# nrf54h20_enga_sysctrl register map
Vendor: Nordic Semiconductor; Series: nRF54h; File version: 1
Registers are 32-bit, read-write, reset 0x0 unless marked. A register's access mark holds for its fields unless they carry their own. Offsets are from the block's base; [hi:lo] are bit positions; lines under a group give offsets from that group; 'fields as' and 'values as' point back to an identical list.

## VREGMRAM130_S — VREGMRAM peripheral 0
Base 0x5F969000
Same registers: VREGMRAM131_S 0x5F96A000
0x00 TASKS_PWRUP wo — Power up the VREF and VPR regulator
  [0] TASKS_PWRUP
    1=Trigger task
0x04 TASKS_PWRDOWN wo — Power down the VREF and VPR regulator
  [0] TASKS_PWRDOWN
    1=Trigger task
0x100 EVENTS_READY — The regulator power up done
  [0] EVENTS_READY
    0=NotGenerated (Event not generated); 1=Generated (Event generated)
0x300 INTEN — Enable or disable interrupt
  [0] READY — Enable or disable interrupt for event READY
    0=Disabled; 1=Enabled
0x304 INTENSET — Enable interrupt
  [0] READY — Write '1' to enable interrupt for event READY
    on read: 0=Disabled (Read: Disabled); 1=Enabled (Read: Enabled) | on write: 1=Set (Enable)
0x308 INTENCLR — Disable interrupt
  [0] READY — Write '1' to disable interrupt for event READY
    on read: 0=Disabled (Read: Disabled); 1=Enabled (Read: Enabled) | on write: 1=Clear (Disable)
0x30C INTPEND ro — Pending interrupts
  [0] READY — Read pending status of interrupt for event READY
    on read: 0=NotPending (Read: Not pending); 1=Pending (Read: Pending)
0x400 STATUSANA ro — Status of analog module output signals
  [0] READY — Current value of the READY signal from the analog module
0x440 TRIM group — Unspecified
  0x00 VBG reset 0x8 — Bandgap voltage buffer trim
    [3:0] VAL — Voltage reference trimming value
  0x04 BIAS — Bias trim
    [1:0] VAL — Bias trimming value
      0=Val450nA (Bias trimming is 450nA); 1=Val530nA (Bias trimming is 530nA); 2=Val400nA (Bias trimming is 400nA)
  0x08 VPR reset 0x8 — VPR reference voltage trim for 1.2V VPR
    [3:0] VAL — Voltage offset trimming value
  0x0C VREF reset 0x8 — VREF reference voltage trim for 0.6V VREF
    [3:0] VAL — Voltage offset trimming value
0x480 MIRROR reset 0x1 — Enable LOCK for mirrored registers
  [0] LOCK — Lock for mirrored registers
    0=Disabled (Lock disabled); 1=Enabled (Lock enabled)
0x484 VPRBLEED reset 0x1 — Enable VPR output load current
  [0] EN — Enable
    0=Disabled (VPR output load current disabled); 1=Enabled (VPR output load current enabled)
0x488 VREFADAPTIVEBIAS reset 0x1 — Adaptive bias enable for VREF
  [0] EN — Enable
    0=Disabled (Adaptive bias is disabled); 1=Enabled (Adaptive bias is enabled)
0x48C VPRADAPTIVEBIAS reset 0x1 — Adaptive bias enable for VPR
  fields as VREFADAPTIVEBIAS
0x490 MODE — MRAM regulator mode
  [0] MODE — Enable
    0=Normal mode; 1=Retain mode
0x500 OVERRIDE group — Unspecified
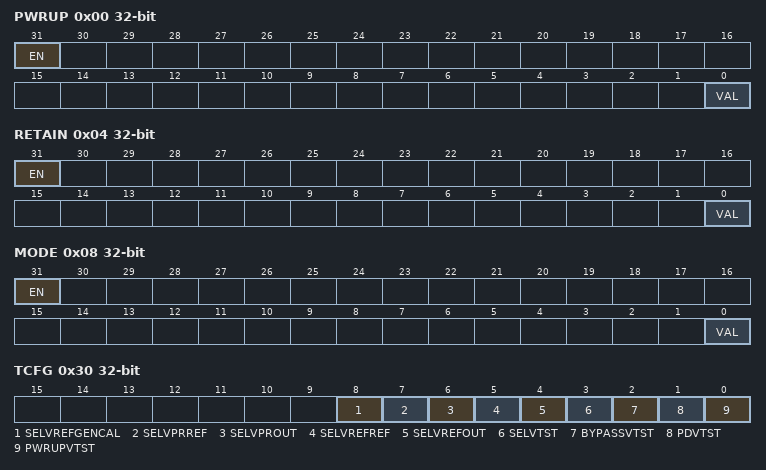
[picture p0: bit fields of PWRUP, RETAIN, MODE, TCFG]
  0x00 PWRUP — Override the PWRUP signal to the analog module
    [31] EN — Enable the override
      0=Disabled (Override is disabled); 1=Enabled (Override is enabled)
    [0] VAL — Override value for the signal
  0x04 RETAIN — Override the RETAIN signal to the analog module
    fields as OVERRIDE.PWRUP
  0x08 MODE — Override the MODE signal to the analog module
    [31] EN — Enable the override
      values as OVERRIDE.PWRUP.EN
    [0] VAL — Current value of the signal
0x600 DFT group — Unspecified
  0x00 ATB0CONFIG — Analog Test Bus 0 (ATB0) configuration
    [31] EN — Enable the analog test bus
      0=Disabled (Analog test bus is disabled); 1=Enabled (Analog test bus is enabled)
    [3] VTST
      0=Disabled (Unspecified); 1=Enabled (Unspecified)
    [2] VPR — VPR 1V2
      0=Disabled (Unspecified); 1=Enabled (Unspecified)
    [1] VREF — VREF 0V6
      0=Disabled (Unspecified); 1=Enabled (Unspecified)
    [0] IB300NA
      0=Disabled (Unspecified); 1=Enabled (Unspecified)
    [3:0] SELMUX — SELMUX 4-bit single signal
  0x04 ATB1CONFIG — Analog Test Bus 1 (ATB1) configuration
    [31] EN — Enable the analog test bus
      values as DFT.ATB0CONFIG.EN
    [2] VPR — VPR 1V2
      0=Disabled (Unspecified); 1=Enabled (Unspecified)
    [1] VREF — VREF 0V6
      0=Disabled (Unspecified); 1=Enabled (Unspecified)
    [0] TSTBFMUX
      0=Disabled (Unspecified); 1=Enabled (Unspecified)
    [2:0] SELMUX — SELMUX 3-bit single signal
  0x30 TCFG — Test mode configuration
    [all] fields
      0=Disabled (Unspecified); 1=Enabled (Unspecified)
    [8] SELVREFGENCAL — Select vref gen v calib to V_TST
    [7] SELVPRREF — Select VPR reference to V_TST
    [6] SELVPROUT — Select VPR VOUT to V_TST
    [5] SELVREFREF — Select VREF reference to V_TST
    [4] SELVREFOUT — Select VREF VOUT to V_TST
    [3] SELVTST — SEL V_TEST buffer to ATB1 mux
    [2] BYPASSVTST — Bypass V_TEST buf to ATB1 mux
    [1] PDVTST — Pull down V_TEST
    [0] PWRUPVTST — PWRUP V_TST to ATB buffer
